# MKV58F20 register map
Vendor: Freescale Semiconductor, Inc.; Series: Kinetis_V; File version: 1.6
CPU: CM7 r0p1, little endian, no MPU, FPU, VTOR, 4 interrupt priority bits
Registers are 32-bit, read-write, reset 0x0 unless marked. A register's access mark holds for its fields unless they carry their own. Offsets are from the block's base; [hi:lo] are bit positions; {n}, {i} and the like mark numbered series; 'fields as' and 'values as' point back to an identical list.

## HSADC0 — SAR Analog to digital converter
Base 0x4005C000; register names take the prefix HSADC0_
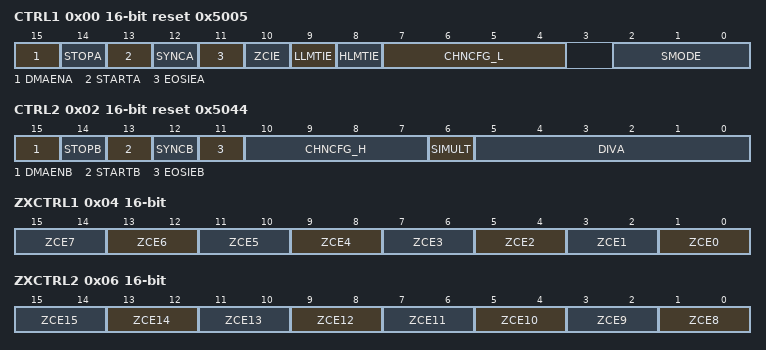
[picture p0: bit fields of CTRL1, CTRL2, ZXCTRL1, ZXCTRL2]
0x00 CTRL1 16-bit reset 0x5005 — HSADC Control Register 1
  [15] DMAENA — DMA enable
    0=DMA is not enabled; 1=DMA is enabled
  [14] STOPA — Stop
    0=Normal operation; 1=Stop mode
  [13] STARTA wo — STARTA Conversion
    0=No action; 1=Start command is issued
  [12] SYNCA — SYNCA Enable
    0=Scan is initiated by a write to CTRL1[STARTA] only; 1=Use a SYNCA input pulse or CTRL1[STARTA] to initiate a scan
  [11] EOSIEA — End Of Scan Interrupt Enable
    0=Interrupt disabled; 1=Interrupt enabled
  [10] ZCIE — Zero Crossing Interrupt Enable
    0=Interrupt disabled; 1=Interrupt enabled
  [9] LLMTIE — Low Limit Interrupt Enable
    0=Interrupt disabled; 1=Interrupt enabled
  [8] HLMTIE — High Limit Interrupt Enable
    0=Interrupt disabled; 1=Interrupt enabled
  [7:4] CHNCFG_L — CHCNF (Channel Configure Low) bits
    0bxxx1=Inputs = ANA0-ANA1; 0bxxx0=Inputs = ANA0-ANA1; 0bxx1x=Inputs = ANA2-ANA3; 0bxx0x=Inputs = ANA2-ANA3; 0bx1xx=Inputs = ANB0-ANB1; 0bx0xx=Inputs = ANB0-ANB1; 0b1xxx=Inputs = ANB2-ANB3
  [2:0] SMODE — HSADC Scan Mode Control
    0=Once (single) sequential; 1=Once parallel; 2=Loop sequential; 3=Loop parallel; 4=Triggered sequential; 5=Triggered parallel (default)
0x02 CTRL2 16-bit reset 0x5044 — HSADC Control Register 2
  [15] DMAENB — DMA enable
    0=DMA is not enabled; 1=DMA is enabled
  [14] STOPB — Stop
    0=Normal operation; 1=Stop mode
  [13] STARTB wo — STARTB Conversion
    0=No action; 1=Start command is issued
  [12] SYNCB — SYNCB Enable
    0=B converter parallel scan is initiated by a write to CTRL2[STARTB] only; 1=Use a SYNCB input pulse or CTRL2[STARTB] to initiate a B converter parallel scan
  [11] EOSIEB — End Of Scan Interrupt Enable
    0=Interrupt disabled; 1=Interrupt enabled
  [10:7] CHNCFG_H — CHNCFG_H (Channel Configure High) bits
    0bxxx1=Inputs = ANA4-ANA5; 0bxxx0=Inputs = ANA4-ANA5; 0bxx1x=Inputs = ANA6-ANA7; 0bxx0x=Inputs = ANA6-ANA7; 0bx1xx=Inputs = ANB4-ANB5; 0bx0xx=Inputs = ANB4-ANB5; 0b1xxx=Inputs = ANB6-ANB7
  [6] SIMULT — Simultaneous mode
    0=Parallel scans done independently; 1=Parallel scans done simultaneously (default)
  [5:0] DIVA — Clock Divisor Select
0x04 ZXCTRL1 16-bit — HSADC Zero Crossing Control 1 Register
  [all] fields
    0=Zero Crossing disabled; 1=Zero Crossing enabled for positive to negative sign change; 2=Zero Crossing enabled for negative to positive sign change; 3=Zero Crossing enabled for any sign change
  [2n+1:2n] ZCE{n} (n=0..7) — Zero crossing enable {n}
0x06 ZXCTRL2 16-bit — HSADC Zero Crossing Control 2 Register
  [all] fields
    values as the fields of ZXCTRL1
  [2n-15:2n-16] ZCE{n} (n=8..15) — Zero crossing enable {n}
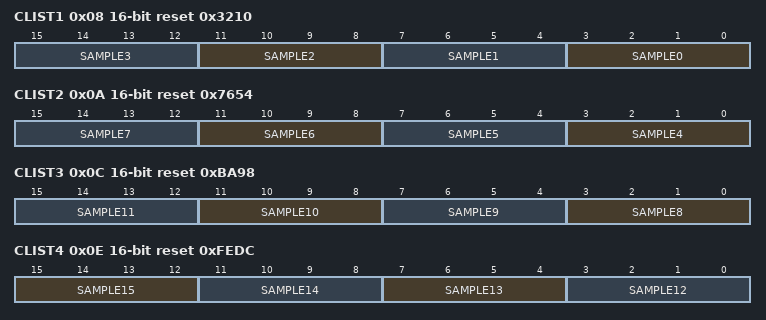
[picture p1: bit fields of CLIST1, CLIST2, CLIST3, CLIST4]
0x08 CLIST1 16-bit reset 0x3210 — HSADC Channel List Register 1
  [all] fields
    0=Single Ended: ANA0, Differential: ANA0+, ANA1-; 1=Single Ended: ANA1, Differential: ANA0+, ANA1-; 2=Single Ended: ANA2, Differential: ANA2+, ANA3-; 3=Single Ended: ANA3, Differential: ANA2+, ANA3-; 4=Single Ended: ANA4, Differential: ANA4+, ANA5-; 5=Single Ended: ANA5, Differential: ANA4+, ANA5-; 6=Single Ended: ANA6, Differential: ANA6+, ANA7-; 7=Single Ended: ANA7, Differential: ANA6+, ANA7-; 8=Single Ended: ANB0, Differential: ANB0+, ANB1-; 9=Single Ended: ANB1, Differential: ANB0+, ANB1-; 10=Single Ended: ANB2, Differential: ANB2+, ANB3-; 11=Single Ended: ANB3, Differential: ANB2+, ANB3-; 12=Single Ended: ANB4, Differential: ANB4+, ANB5-; 13=Single Ended: ANB5, Differential: ANB4+, ANB5-; 14=Single Ended: ANB6, Differential: ANB6+, ANB7-; 15=Single Ended: ANB7, Differential: ANB6+, ANB7-
  [4n+3:4n] SAMPLE{n} (n=0..3) — Sample Field {n}
0x0A CLIST2 16-bit reset 0x7654 — HSADC Channel List Register 2
  [all] fields
    values as the fields of CLIST1
  [4n-13:4n-16] SAMPLE{n} (n=4..7) — Sample Field {n}
0x0C CLIST3 16-bit reset 0xBA98 — HSADC Channel List Register 3
  [all] fields
    values as the fields of CLIST1
  [4n-29:4n-32] SAMPLE{n} (n=8..11) — Sample Field {n}
0x0E CLIST4 16-bit reset 0xFEDC — HSADC Channel List Register 4
  [15:12] SAMPLE15 — Sample Field 15
    0=Single Ended: ANA0, Differential: ANA0+, ANA1-; 1=Single Ended: ANA1, Differential: ANA0+, ANA1-; 2=Single Ended: ANA2, Differential: ANA2+, ANA3-; 3=Single Ended: ANA3, Differential: ANA2+, ANA3-; 4=Single Ended: ANA4, Differential: ANA4+, ANA5-; 5=Single Ended: ANA5, Differential: ANA4+, ANA5-; 6=Single Ended: ANA6, Differential: ANA6+, ANA7-; 7=Single Ended: ANA7, Differential: ANA6+, ANA7-; 8=Single Ended: ANB0, Differential: ANB0+, ANB1-; 9=Single Ended: ANB1, Differential: ANB0+, ANB1-; 10=Single Ended: ANB2, Differential: ANB2+, ANB3-; 11=Single Ended: ANB3, Differential: ANB2+, ANB3-; 12=Single Ended: ANB4, Differential: ANB4+, ANB5-; 13=Single Ended: ANB5, Differential: ANB4+, ANB5-; 14=Single Ended: ANB6, Differential: ANB6+, ANB7-. See Input Multiplex Function section for more details.; 15=Single Ended: ANB7, Differential: ANB6+, ANB7-
  [11:8] SAMPLE14 — Sample Field 14
    values as the fields of CLIST1
  [7:4] SAMPLE13 — Sample Field 13
    values as the fields of CLIST1
  [3:0] SAMPLE12 — Sample Field 12
    values as the fields of CLIST1
0x10 SDIS 16-bit reset 0xF0F0 — HSADC Sample Disable Register
  [15:0] DS — Disable Sample Bits
    0=SAMPLEx channel is enabled for HSADC scan; 1=SAMPLEx channel is disabled for HSADC scan and corresponding channels after SAMPLEx will also not occur in an HSADC scan
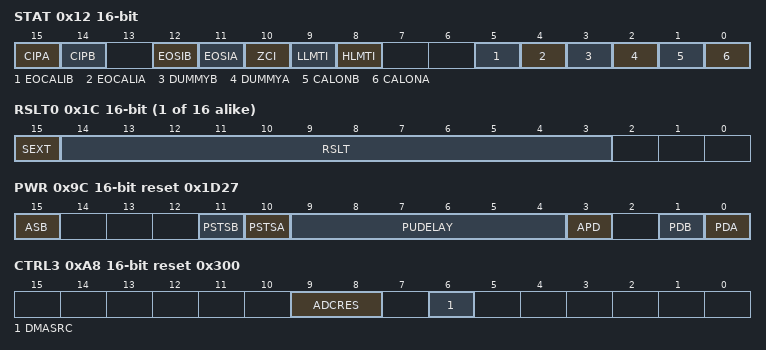
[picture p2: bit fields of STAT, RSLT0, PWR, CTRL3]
0x12 STAT 16-bit — HSADC Status Register
  [15] CIPA ro — Conversion in Progress
    0=Idle state; 1=A scan cycle is in progress. The HSADC will ignore all sync pulses or start commands
  [14] CIPB ro — Conversion in Progress
    values as CIPA
  [12] EOSIB — End of Scan Interrupt
    0=A scan cycle has not been completed, no end of scan IRQ pending; 1=A scan cycle has been completed, end of scan IRQ pending
  [11] EOSIA — End of Scan Interrupt
    values as EOSIB
  [10] ZCI ro — Zero Crossing Interrupt
    0=No zero crossing interrupt request; 1=Zero crossing encountered, IRQ pending if CTRL1[ZCIE] is set
  [9] LLMTI ro — Low Limit Interrupt
    0=No low limit interrupt request; 1=Low limit exceeded, IRQ pending if CTRL1[LLMTIE] is set
  [8] HLMTI ro — High Limit Interrupt
    0=No high limit interrupt request; 1=High limit exceeded, IRQ pending if CTRL1[HLMTIE] is set
  [5] EOCALIB — End of Calibration on ADCB Interrupt
    0=Calibration is not finished; 1=Calibration is finished on ADCB. The IRQ occurs if CALIB[EOCALIEB] is asserted.
  [4] EOCALIA — End of Calibration on ADCA Interrupt
    0=Calibration is not finished; 1=Calibration is finished on ADCA. The IRQ occurs if CALIB[EOCALIEA] is asserted.
  [3] DUMMYB ro — Dummy conversion running on HSADCB
    0=Dummy conversion is not running; 1=Dummy conversion is running on ADCB
  [2] DUMMYA ro — Dummy conversion running on HSADCA
    0=Dummy conversion is not running; 1=Dummy conversion is running on ADCA
  [1] CALONB ro — HSADCB Calibration execution status
    0=Calibration is not running; 1=ADCB is running calibration conversions
  [0] CALONA ro — HSADCA Calibration execution status
    0=Calibration is not running; 1=ADCA is running calibration conversions
0x14 RDY 16-bit ro — HSADC Ready Register
  [15:0] RDY — Ready Sample
    0=Sample not ready or has been read; 1=Sample ready to be read
0x16 LOLIMSTAT 16-bit — HSADC Low Limit Status Register
  [15:0] LLS — Low Limit Status Bits
0x18 HILIMSTAT 16-bit — HSADC High Limit Status Register
  [15:0] HLS — High Limit Status Bits
0x1A ZXSTAT 16-bit — HSADC Zero Crossing Status Register
  [15:0] ZCS — Zero Crossing Status
    0=Either: A sign change did not occur in a comparison between the current channelx result and the previous channelx result, or Zero crossing control is disabled for channelx in the zero crossing control register, ZXCTRL; 1=In a comparison between the current channelx result and the previous channelx result, a sign change condition occurred as defined in the zero crossing control register (ZXCTRL)
{0x1C+2i} RSLT{i} (i=0..15) 16-bit — HSADC Result Registers with sign extension
  [15] SEXT ro — Sign Extend
  [14:3] RSLT — Digital Result of the Conversion
{0x3C+2i} LOLIM{i} (i=0..15) 16-bit — HSADC Low Limit Registers
  [14:3] LLMT — Low Limit Bits
{0x5C+2i} HILIM{i} (i=0..15) 16-bit reset 0x7FF8 — HSADC High Limit Registers
  [14:3] HLMT — High Limit Bits
{0x7C+2i} OFFST{i} (i=0..15) 16-bit — HSADC Offset Register
  [14:3] OFFSET — HSADC Offset Bits
0x9C PWR 16-bit reset 0x1D27 — HSADC Power Control Register
  [15] ASB — Auto Standby
    0=Auto standby mode disabled; 1=Auto standby mode enabled
  [11] PSTSB ro — ADC Converter B Power Status
    0=ADC Converter B is currently powered up; 1=ADC Converter B is currently powered down
  [10] PSTSA ro — ADC Converter A Power Status
    0=ADC Converter A is currently powered up; 1=ADC Converter A is currently powered down
  [9:4] PUDELAY — Power Up Delay
  [3] APD — Auto Powerdown
    0=Auto Powerdown Mode is not active; 1=Auto Powerdown Mode is active
  [1] PDB — Manual Power Down for Converter B
    0=Power Up ADC converter B; 1=Power Down ADC converter B
  [0] PDA — Manual Power Down for Converter A
    0=Power Up ADC converter A; 1=Power Down ADC converter A
0xA4 SCTRL 16-bit — HSADC Scan Control Register
  [15:0] SC — Scan Control Bits
    0=Perform sample immediately after the completion of the current sample; 1=Delay sample until a new sync input occurs
0xA6 PWR2 16-bit reset 0x400 — HSADC Power Control Register 2
  [13:8] DIVB — Clock Divisor Select
0xA8 CTRL3 16-bit reset 0x300 — HSADC Control Register 3
  [9:8] ADCRES — ADCA/B Conversion Resolution
    0=6-bit mode; 1=8-bit mode; 2=10-bit mode; 3=12-bit mode
  [6] DMASRC — DMA Trigger Source
    0=DMA trigger source is end of scan interrupt; 1=DMA trigger source is RDY bits
0xAA SCINTEN 16-bit — HSADC Scan Interrupt Enable Register
  [15:0] SCINTEN — Scan Interrupt Enable
    0=Scan interrupt is not enabled for this sample; 1=Scan interrupt is enabled for this sample
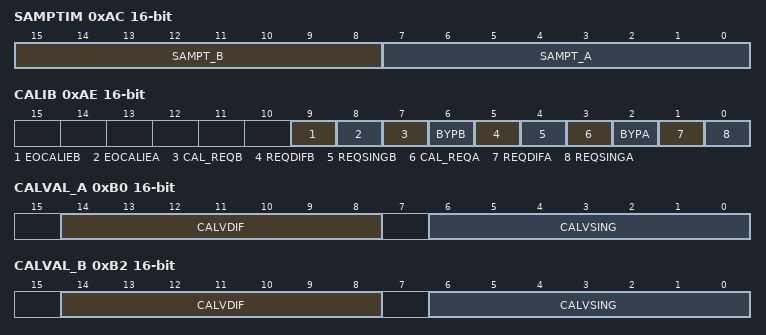
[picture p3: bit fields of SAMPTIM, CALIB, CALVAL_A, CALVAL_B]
0xAC SAMPTIM 16-bit — HSADC Sampling Time Configuration Register
  [15:8] SAMPT_B — Sampling Time for ADCB.
  [7:0] SAMPT_A — Sampling Time for ADCA.
0xAE CALIB 16-bit — HSADCs Calibration Configuration
  [9] EOCALIEB — Interrupt Enable for End of Calibration on ADCB
    0=Interrupt is not enabled; 1=Interrupt is enabled
  [8] EOCALIEA — Interrupt Enable for End of Calibration on ADCA
    0=Interrupt is not enabled; 1=Interrupt is enabled
  [7] CAL_REQB wo — Calibration Request for ADCB
    0=Calibration is not requested; 1=Calibration is requested for ADCB
  [6] BYPB — ADCB calibration bypass
    0=ADCB block uses the calibration values to obtain the final conversion result (differential or single-ended mode); 1=Calibration operation is bypassed on ADCB
  [5] REQDIFB — ADCB Calibration request for differential mode
    0=Calibration value calculation is not requested to be run on ADCB; 1=Calibration value calculation for differential input mode is requested to be run onr ADCB
  [4] REQSINGB — ADCB Calibration request for single ended mode
    0=Calibration value calculation is not requested to be run on ADCB; 1=Calibration value calculation for single-ended input mode is requested to be run on ADCB
  [3] CAL_REQA wo — Calibration Request for ADCA
    0=None; 1=Calibration request for ADCA
  [2] BYPA — ADCA calibration bypass
    0=ADCA block uses the calibration values to obtain the final conversion result (differential or single-ended mode); 1=Calibration operation is bypassed on ADCA
  [1] REQDIFA — ADCA Calibration request for differential mode
    0=Calibration value calculation is not requested to ADCA; 1=Calibration value calculation for differential input mode is requested to be run on ADCA
  [0] REQSINGA — ADCA Calibration request for single ended mode
    0=Calibration value calculation is not requested to be run on ADCA; 1=Calibration value calculation for single-ended input mode is requested to be run on ADCA
0xB0 CALVAL_A 16-bit — Calibration Values for ADCA Register
  [14:8] CALVDIF — Differential mode calibration value for ADCA
  [6:0] CALVSING — Single-ended mode calibration value for ADCA
0xB2 CALVAL_B 16-bit — Calibration Values for ADCB Register
  [14:8] CALVDIF — Differential mode calibration value
  [6:0] CALVSING — Single-ended mode calibration value
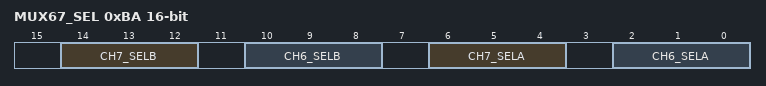
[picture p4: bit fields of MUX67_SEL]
0xBA MUX67_SEL 16-bit — MUX6_7 Selection Controls Register
  [14:12] CH7_SELB — ADCB Channel 7 additional MUX Selector
  [10:8] CH6_SELB — ADCB Channel 6 additional MUX Selector
  [6:4] CH7_SELA — ADCA Channel 7 additional MUX Selector
  [2:0] CH6_SELA — ADCA Channel 6 additional MUX Selector

## HSADC1 — SAR Analog to digital converter
Base 0x400DC000; register names take the prefix HSADC1_
Registers as HSADC0.
